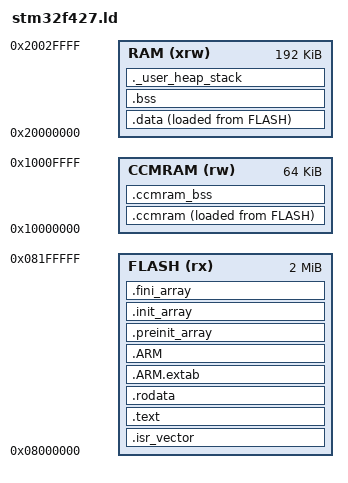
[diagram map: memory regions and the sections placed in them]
/* Linker script for STM32F427VI — standalone DOOM firmware (xBuddy)
 * 2 MB flash @ 0x08000000, 192 KB SRAM @ 0x20000000, 64 KB CCM @ 0x10000000.
 * No bootloader offset: image starts at the very beginning of flash. */

ENTRY(Reset_Handler)

_estack = 0x20030000;          /* top of 192 KB SRAM */
_Min_Heap_Size  = 0x8000;      /* 32 KB heap (Doom zone is allocated statically elsewhere) */
_Min_Stack_Size = 0x2000;      /* 8 KB stack */

MEMORY
{
  FLASH  (rx)  : ORIGIN = 0x08000000, LENGTH = 2048K
  RAM    (xrw) : ORIGIN = 0x20000000, LENGTH = 192K
  CCMRAM (rw)  : ORIGIN = 0x10000000, LENGTH = 64K
}

SECTIONS
{
  .isr_vector :
  {
    . = ALIGN(4);
    KEEP(*(.isr_vector))
    . = ALIGN(4);
  } >FLASH

  .text :
  {
    . = ALIGN(4);
    *(.text)
    *(.text*)
    *(.glue_7)
    *(.glue_7t)
    *(.eh_frame)
    KEEP (*(.init))
    KEEP (*(.fini))
    . = ALIGN(4);
    _etext = .;
  } >FLASH

  .rodata :
  {
    . = ALIGN(4);
    *(.rodata)
    *(.rodata*)
    . = ALIGN(4);
  } >FLASH

  .ARM.extab : { *(.ARM.extab* .gnu.linkonce.armextab.*) } >FLASH
  .ARM : {
    __exidx_start = .;
    *(.ARM.exidx*)
    __exidx_end = .;
  } >FLASH

  .preinit_array :
  {
    PROVIDE_HIDDEN (__preinit_array_start = .);
    KEEP (*(.preinit_array*))
    PROVIDE_HIDDEN (__preinit_array_end = .);
  } >FLASH
  .init_array :
  {
    PROVIDE_HIDDEN (__init_array_start = .);
    KEEP (*(SORT(.init_array.*)))
    KEEP (*(.init_array*))
    PROVIDE_HIDDEN (__init_array_end = .);
  } >FLASH
  .fini_array :
  {
    PROVIDE_HIDDEN (__fini_array_start = .);
    KEEP (*(SORT(.fini_array.*)))
    KEEP (*(.fini_array*))
    PROVIDE_HIDDEN (__fini_array_end = .);
  } >FLASH

  _sidata = LOADADDR(.data);
  .data :
  {
    . = ALIGN(4);
    _sdata = .;
    *(.data)
    *(.data*)
    *(.RamFunc)
    *(.RamFunc*)
    . = ALIGN(4);
    _edata = .;
  } >RAM AT> FLASH

  . = ALIGN(4);
  .bss :
  {
    _sbss = .;
    __bss_start__ = _sbss;
    *(.bss)
    *(.bss*)
    *(COMMON)
    . = ALIGN(4);
    _ebss = .;
    __bss_end__ = _ebss;
  } >RAM

  /* CCM RAM: 64 KB, not DMA-capable. Place explicitly-tagged data here. */
  _siccmram = LOADADDR(.ccmram);
  .ccmram :
  {
    . = ALIGN(4);
    _sccmram = .;
    *(.ccmram)
    *(.ccmram*)
    . = ALIGN(4);
    _eccmram = .;
  } >CCMRAM AT> FLASH

  .ccmram_bss (NOLOAD) :
  {
    . = ALIGN(4);
    _sccmram_bss = .;
    *(.ccmram_bss)
    *(.ccmram_bss*)
    . = ALIGN(4);
    _eccmram_bss = .;
  } >CCMRAM

  ._user_heap_stack :
  {
    . = ALIGN(8);
    PROVIDE ( end = . );
    PROVIDE ( _end = . );
    . = . + _Min_Heap_Size;
    . = . + _Min_Stack_Size;
    . = ALIGN(8);
  } >RAM

  .ARM.attributes 0 : { *(.ARM.attributes) }
}
